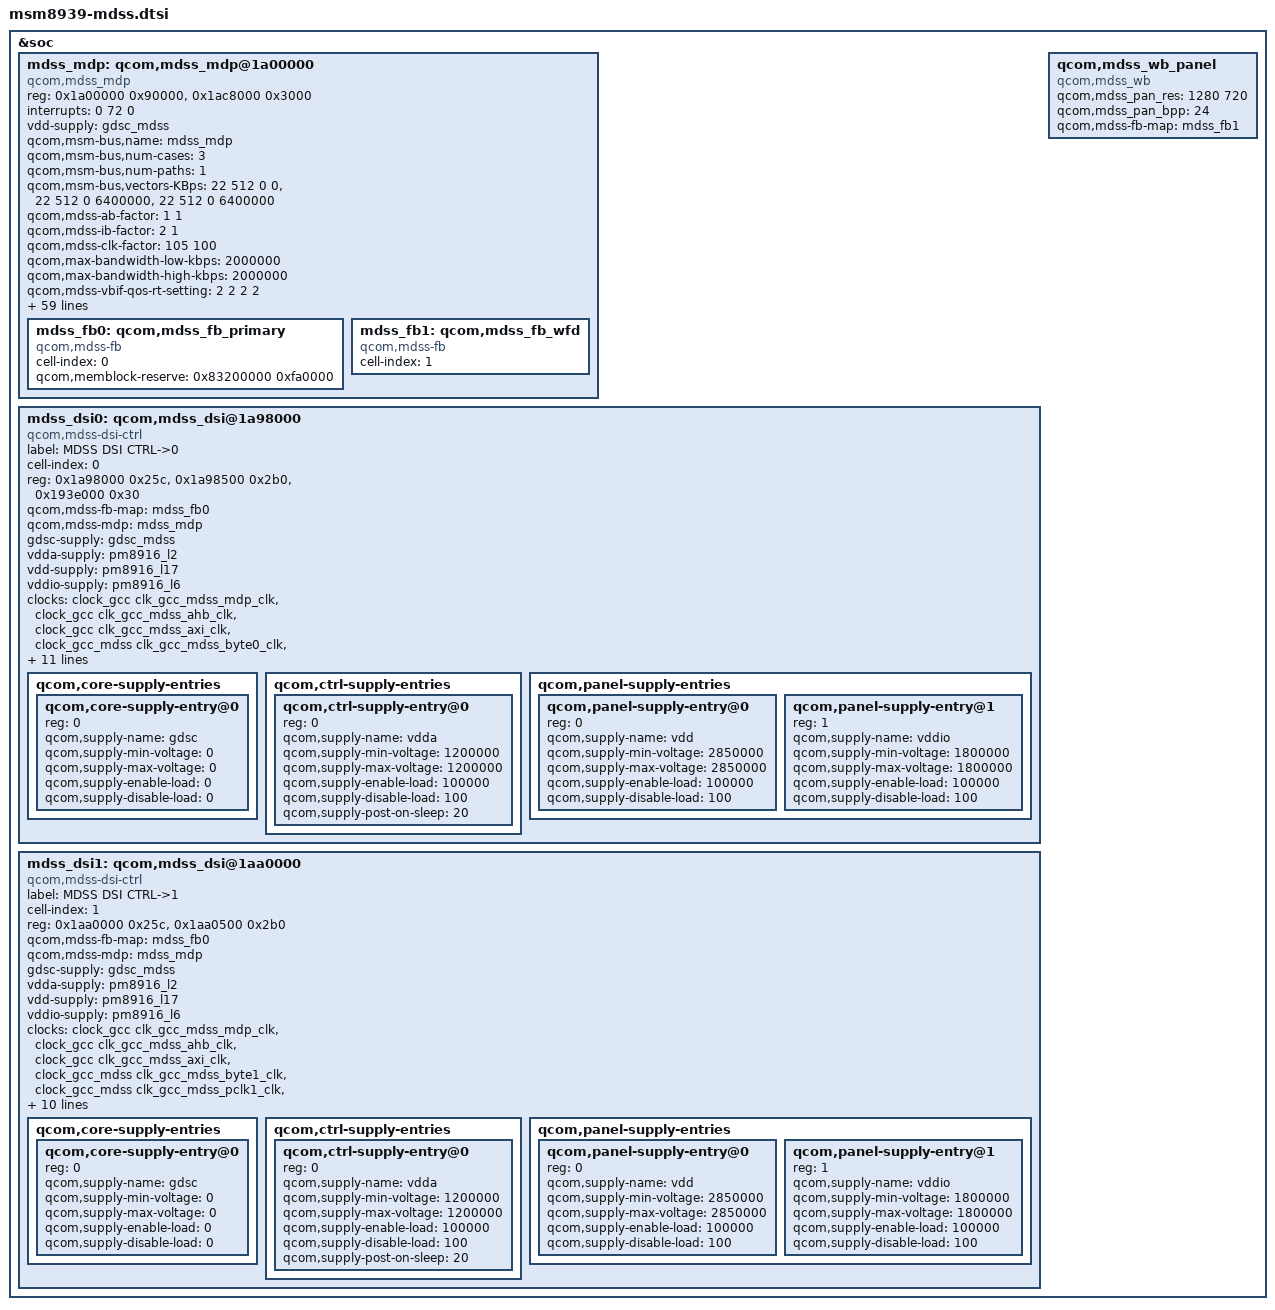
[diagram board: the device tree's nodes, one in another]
/* Copyright (c) 2014, The Linux Foundation. All rights reserved.
 *
 * This program is free software; you can redistribute it and/or modify
 * it under the terms of the GNU General Public License version 2 and
 * only version 2 as published by the Free Software Foundation.
 *
 * This program is distributed in the hope that it will be useful,
 * but WITHOUT ANY WARRANTY; without even the implied warranty of
 * MERCHANTABILITY or FITNESS FOR A PARTICULAR PURPOSE.  See the
 * GNU General Public License for more details.
 */

&soc {
	mdss_mdp: qcom,mdss_mdp@1a00000 {
		compatible = "qcom,mdss_mdp";
		reg = <0x1a00000 0x90000>,
			<0x1ac8000 0x3000>;
		reg-names = "mdp_phys", "vbif_phys";
		interrupts = <0 72 0>;
		vdd-supply = <&gdsc_mdss>;

		/* Bus Scale Settings */
		qcom,msm-bus,name = "mdss_mdp";
		qcom,msm-bus,num-cases = <3>;
		qcom,msm-bus,num-paths = <1>;
		qcom,msm-bus,vectors-KBps =
			<22 512 0 0>,
			<22 512 0 6400000>,
			<22 512 0 6400000>;

		/* Fudge factors */
		qcom,mdss-ab-factor = <1 1>;		/* 1 times    */
		qcom,mdss-ib-factor = <2 1>;		/* 2 times  */
		qcom,mdss-clk-factor = <105 100>;	/* 1.05 times */
		qcom,max-bandwidth-low-kbps = <2000000>;
		qcom,max-bandwidth-high-kbps = <2000000>;

		/* VBIF QoS remapper settings*/
		qcom,mdss-vbif-qos-rt-setting = <2 2 2 2>;
		qcom,mdss-vbif-qos-nrt-setting = <1 1 1 1>;
		qcom,max-mixer-width = <2560>;
		qcom,mdss-mdp-reg-offset = <0x00001000>;
		qcom,max-clk-rate = <320000000>;
		qcom,mdss-pipe-vig-off = <0x00005000>;
		qcom,mdss-pipe-rgb-off = <0x00015000 0x00017000>;
		qcom,mdss-pipe-dma-off = <0x00025000>;
		qcom,mdss-pipe-vig-fetch-id = <1>;
		qcom,mdss-pipe-rgb-fetch-id = <7 8>;
		qcom,mdss-pipe-dma-fetch-id = <4>;

		qcom,mdss-pipe-vig-xin-id = <0>;
		qcom,mdss-pipe-rgb-xin-id = <1 5>;
		qcom,mdss-pipe-dma-xin-id = <2>;

		qcom,mdss-has-panic-ctrl;
		/* Panic/robust control register offsets for pipes */
		qcom,mdss-pipe-vig-panic-ctrl-offsets = <0>;
		qcom,mdss-pipe-rgb-panic-ctrl-offsets = <4 5>;
		qcom,mdss-pipe-dma-panic-ctrl-offsets = <8>;

		qcom,mdss-pipe-vig-clk-ctrl-offsets = <0x2ac 0 0>;
		qcom,mdss-pipe-rgb-clk-ctrl-offsets = <0x2ac 4 8>,
						      <0x2b4 4 8>;
		qcom,mdss-pipe-dma-clk-ctrl-offsets = <0x2ac 8 12>;

		qcom,mdss-smp-data = <8 10240>;

		qcom,mdss-ctl-off = <0x00002000 0x00002200 0x00002400>;
		qcom,mdss-mixer-intf-off = <0x00045000>;
		qcom,mdss-mixer-wb-off = <0x00048000>;
		qcom,mdss-dspp-off = <0x00055000>;
		qcom,mdss-pingpong-off = <0x00071000>;
		qcom,mdss-wb-off = <0x00065000 0x00065800 0x00066000>;
		qcom,mdss-intf-off = <0x00000000 0x0006b800 0x0006c000>;
		qcom,mdss-rot-block-size = <64>;
		qcom,mdss-wfd-mode = "dedicated";
		qcom,mdss-has-non-scalar-rgb;
		qcom,mdss-has-decimation;
		qcom,mdss-has-fixed-qos-arbiter-enabled;
		qcom,mdss-has-dst-split;

		vdd-cx-supply = <&pm8916_s1_corner>;
		clocks = <&clock_gcc clk_gcc_mdss_ahb_clk>,
			 <&clock_gcc clk_gcc_mdss_axi_clk>,
			 <&clock_gcc clk_mdp_clk_src>,
			 <&clock_gcc clk_gcc_mdss_mdp_clk>,
			 <&clock_gcc clk_gcc_mdss_vsync_clk>;
		clock-names = "iface_clk", "bus_clk", "core_clk_src",
				"core_clk", "vsync_clk";
		qcom,mdp-settings = <0x0000117C 0x00005555>,
				    <0x000011e4 0x00000000>,
				    <0x00065048 0x00000008>,
				    <0x00065848 0x00000008>,
				    <0x00066048 0x00000008>;

		/* buffer parameters to calculate prefill bandwidth */
		qcom,mdss-prefill-outstanding-buffer-bytes = <2048>;
		qcom,mdss-prefill-y-buffer-bytes = <0>;
		qcom,mdss-prefill-scaler-buffer-lines-bilinear = <2>;
		qcom,mdss-prefill-scaler-buffer-lines-caf = <4>;
		qcom,mdss-prefill-post-scaler-buffer-pixels = <2560>;
		qcom,mdss-prefill-pingpong-buffer-pixels = <6400>;
		qcom,mdss-prefill-fbc-lines = <2>;

		mdss_fb0: qcom,mdss_fb_primary {
			cell-index = <0>;
			compatible = "qcom,mdss-fb";
			qcom,memblock-reserve = <0x83200000 0xfa0000>;
		};

		mdss_fb1: qcom,mdss_fb_wfd {
			cell-index = <1>;
			compatible = "qcom,mdss-fb";
		};
	};

	mdss_dsi0: qcom,mdss_dsi@1a98000 {
		compatible = "qcom,mdss-dsi-ctrl";
		label = "MDSS DSI CTRL->0";
		cell-index = <0>;
		reg = <0x1a98000 0x25c>,
		      <0x1a98500 0x2b0>,
		      <0x193e000 0x30>;
		reg-names = "dsi_ctrl", "dsi_phy", "mmss_misc_phys";
		qcom,mdss-fb-map = <&mdss_fb0>;
		qcom,mdss-mdp = <&mdss_mdp>;
		gdsc-supply = <&gdsc_mdss>;
		vdda-supply = <&pm8916_l2>;
		vdd-supply = <&pm8916_l17>;
		vddio-supply = <&pm8916_l6>;
		clocks = <&clock_gcc clk_gcc_mdss_mdp_clk>,
			 <&clock_gcc clk_gcc_mdss_ahb_clk>,
			 <&clock_gcc clk_gcc_mdss_axi_clk>,
			 <&clock_gcc_mdss clk_gcc_mdss_byte0_clk>,
			 <&clock_gcc_mdss clk_gcc_mdss_pclk0_clk>,
			 <&clock_gcc clk_gcc_mdss_esc0_clk>;
		clock-names = "mdp_core_clk", "iface_clk", "bus_clk",
				"byte_clk", "pixel_clk", "core_clk";
		qcom,regulator-ldo-mode;
		qcom,platform-strength-ctrl = [ff 06];
		qcom,platform-bist-ctrl = [00 00 b1 ff 00 00];
		qcom,platform-regulator-settings = [02 09 03 00 20 00 01];
		qcom,platform-lane-config = [00 00 00 00 00 00 00 01 97
			00 00 00 00 05 00 00 01 97
			00 00 00 00 0a 00 00 01 97
			00 00 00 00 0f 00 00 01 97
			00 c0 00 00 00 00 00 01 bb];

		qcom,mmss-ulp-clamp-ctrl-offset = <0x20>;
		qcom,mmss-phyreset-ctrl-offset = <0x24>;

		qcom,core-supply-entries {
                        #address-cells = <1>;
                        #size-cells = <0>;
                        qcom,core-supply-entry@0 {
                                reg = <0>;
                                qcom,supply-name = "gdsc";
                                qcom,supply-min-voltage = <0>;
                                qcom,supply-max-voltage = <0>;
                                qcom,supply-enable-load = <0>;
                                qcom,supply-disable-load = <0>;
                        };
                };

		qcom,ctrl-supply-entries {
                        #address-cells = <1>;
                        #size-cells = <0>;
                        qcom,ctrl-supply-entry@0 {
                                reg = <0>;
                                qcom,supply-name = "vdda";
                                qcom,supply-min-voltage = <1200000>;
                                qcom,supply-max-voltage = <1200000>;
                                qcom,supply-enable-load = <100000>;
                                qcom,supply-disable-load = <100>;
                                qcom,supply-post-on-sleep = <20>;
                        };
                };

		qcom,panel-supply-entries {
                        #address-cells = <1>;
                        #size-cells = <0>;
                        qcom,panel-supply-entry@0 {
                                reg = <0>;
                                qcom,supply-name = "vdd";
                                qcom,supply-min-voltage = <2850000>;
                                qcom,supply-max-voltage = <2850000>;
                                qcom,supply-enable-load = <100000>;
                                qcom,supply-disable-load = <100>;
                        };
                        qcom,panel-supply-entry@1 {
                                reg = <1>;
                                qcom,supply-name = "vddio";
                                qcom,supply-min-voltage = <1800000>;
                                qcom,supply-max-voltage = <1800000>;
                                qcom,supply-enable-load = <100000>;
                                qcom,supply-disable-load = <100>;
                        };
                };
	};

	mdss_dsi1: qcom,mdss_dsi@1aa0000 {
		compatible = "qcom,mdss-dsi-ctrl";
		label = "MDSS DSI CTRL->1";
		cell-index = <1>;
		reg = <0x1aa0000 0x25c>,
		      <0x1aa0500 0x2b0>;
		reg-names = "dsi_ctrl", "dsi_phy";
		qcom,mdss-fb-map = <&mdss_fb0>;
		qcom,mdss-mdp = <&mdss_mdp>;
		gdsc-supply = <&gdsc_mdss>;
		vdda-supply = <&pm8916_l2>;
		vdd-supply = <&pm8916_l17>;
		vddio-supply = <&pm8916_l6>;
		clocks = <&clock_gcc clk_gcc_mdss_mdp_clk>,
			 <&clock_gcc clk_gcc_mdss_ahb_clk>,
			 <&clock_gcc clk_gcc_mdss_axi_clk>,
			 <&clock_gcc_mdss clk_gcc_mdss_byte1_clk>,
			 <&clock_gcc_mdss clk_gcc_mdss_pclk1_clk>,
			 <&clock_gcc clk_gcc_mdss_esc1_clk>;
		clock-names = "mdp_core_clk", "iface_clk", "bus_clk",
				"byte_clk", "pixel_clk", "core_clk";
		qcom,platform-strength-ctrl = [ff 06];
		qcom,platform-bist-ctrl = [00 00 b1 ff 00 00];
		qcom,regulator-ldo-mode;
		qcom,platform-regulator-settings = [02 09 03 00 20 00 01];
		qcom,platform-lane-config = [00 00 00 00 00 00 00 01 97
			00 00 00 00 05 00 00 01 97
			00 00 00 00 0a 00 00 01 97
			00 00 00 00 0f 00 00 01 97
			00 c0 00 00 00 00 00 01 bb];

		qcom,mmss-ulp-clamp-ctrl-offset = <0x20>;
		qcom,mmss-phyreset-ctrl-offset = <0x24>;

		qcom,core-supply-entries {
			#address-cells = <1>;
			#size-cells = <0>;
			qcom,core-supply-entry@0 {
				reg = <0>;
				qcom,supply-name = "gdsc";
				qcom,supply-min-voltage = <0>;
				qcom,supply-max-voltage = <0>;
				qcom,supply-enable-load = <0>;
				qcom,supply-disable-load = <0>;
			};
		};

		qcom,ctrl-supply-entries {
			#address-cells = <1>;
			#size-cells = <0>;
			qcom,ctrl-supply-entry@0 {
				reg = <0>;
				qcom,supply-name = "vdda";
				qcom,supply-min-voltage = <1200000>;
				qcom,supply-max-voltage = <1200000>;
				qcom,supply-enable-load = <100000>;
				qcom,supply-disable-load = <100>;
				qcom,supply-post-on-sleep = <20>;
			};
		};

		qcom,panel-supply-entries {
			#address-cells = <1>;
			#size-cells = <0>;
			qcom,panel-supply-entry@0 {
				reg = <0>;
				qcom,supply-name = "vdd";
				qcom,supply-min-voltage = <2850000>;
				qcom,supply-max-voltage = <2850000>;
				qcom,supply-enable-load = <100000>;
				qcom,supply-disable-load = <100>;
			};
			qcom,panel-supply-entry@1 {
				reg = <1>;
				qcom,supply-name = "vddio";
				qcom,supply-min-voltage = <1800000>;
				qcom,supply-max-voltage = <1800000>;
				qcom,supply-enable-load = <100000>;
				qcom,supply-disable-load = <100>;
			};
		};
	};

	qcom,mdss_wb_panel {
		compatible = "qcom,mdss_wb";
		qcom,mdss_pan_res = <1280 720>;
		qcom,mdss_pan_bpp = <24>;
		qcom,mdss-fb-map = <&mdss_fb1>;
	};
};

#include "dsi-panel-sim-video.dtsi"

